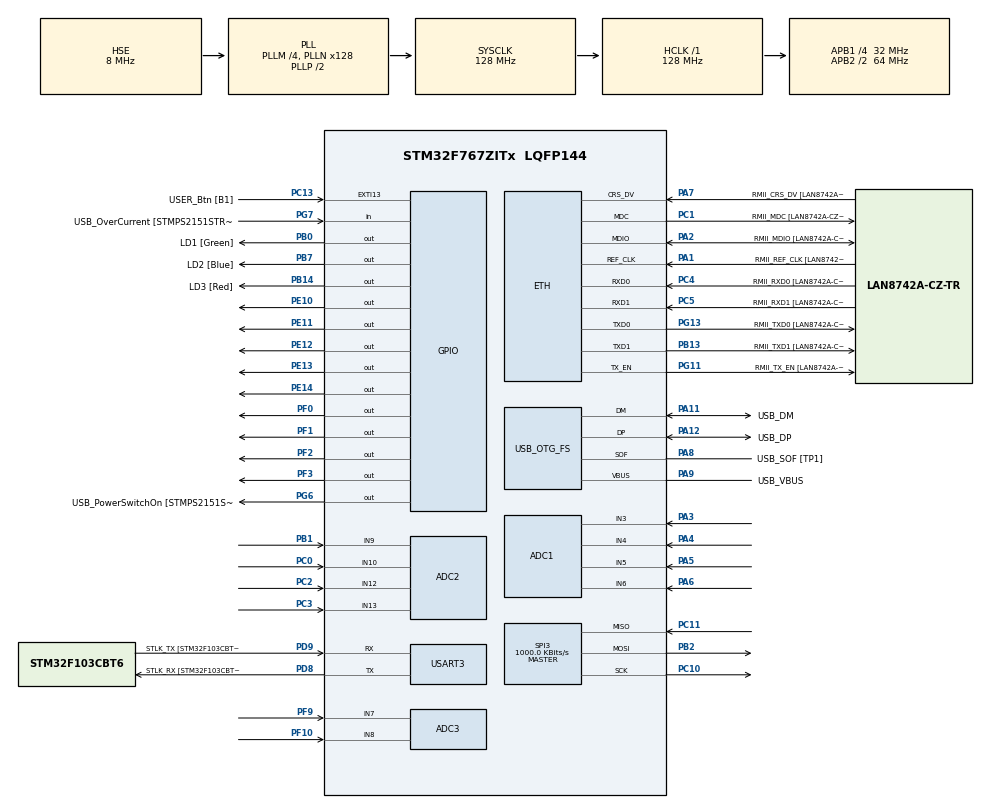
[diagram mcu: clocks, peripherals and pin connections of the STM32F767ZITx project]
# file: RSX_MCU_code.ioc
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ADC1.Channel-4\#ChannelRegularConversion=ADC_CHANNEL_3
ADC1.Channel-5\#ChannelRegularConversion=ADC_CHANNEL_4
ADC1.Channel-6\#ChannelRegularConversion=ADC_CHANNEL_5
ADC1.Channel-7\#ChannelRegularConversion=ADC_CHANNEL_6
ADC1.ClockPrescaler=ADC_CLOCK_SYNC_PCLK_DIV4
ADC1.ContinuousConvMode=ENABLE
ADC1.DMAContinuousRequests=ENABLE
ADC1.NbrOfConversion=4
ADC1.NbrOfConversionFlag=1
ADC1.Rank-4\#ChannelRegularConversion=1
ADC1.Rank-5\#ChannelRegularConversion=2
ADC1.Rank-6\#ChannelRegularConversion=3
ADC1.Rank-7\#ChannelRegularConversion=4
ADC1.SamplingTime-4\#ChannelRegularConversion=ADC_SAMPLETIME_3CYCLES
ADC1.SamplingTime-5\#ChannelRegularConversion=ADC_SAMPLETIME_3CYCLES
ADC1.SamplingTime-6\#ChannelRegularConversion=ADC_SAMPLETIME_3CYCLES
ADC1.SamplingTime-7\#ChannelRegularConversion=ADC_SAMPLETIME_3CYCLES
ADC1.ScanConvMode=ADC_SCAN_ENABLE
ADC1.master=1
ADC2.Channel-1\#ChannelRegularConversion=ADC_CHANNEL_9
ADC2.Channel-2\#ChannelRegularConversion=ADC_CHANNEL_10
ADC2.Channel-3\#ChannelRegularConversion=ADC_CHANNEL_12
ADC2.Channel-4\#ChannelRegularConversion=ADC_CHANNEL_13
ADC2.ClockPrescaler=ADC_CLOCK_SYNC_PCLK_DIV4
ADC2.ContinuousConvMode=ENABLE
ADC2.DMAContinuousRequests=ENABLE
ADC2.NbrOfConversion=4
ADC2.NbrOfConversionFlag=1
ADC2.Rank-1\#ChannelRegularConversion=1
ADC2.Rank-2\#ChannelRegularConversion=2
ADC2.Rank-3\#ChannelRegularConversion=3
ADC2.Rank-4\#ChannelRegularConversion=4
ADC2.SamplingTime-1\#ChannelRegularConversion=ADC_SAMPLETIME_3CYCLES
ADC2.SamplingTime-2\#ChannelRegularConversion=ADC_SAMPLETIME_3CYCLES
ADC2.SamplingTime-3\#ChannelRegularConversion=ADC_SAMPLETIME_3CYCLES
ADC2.SamplingTime-4\#ChannelRegularConversion=ADC_SAMPLETIME_3CYCLES
ADC2.ScanConvMode=ADC_SCAN_ENABLE
ADC3.Channel-0\#ChannelRegularConversion=ADC_CHANNEL_7
ADC3.Channel-1\#ChannelRegularConversion=ADC_CHANNEL_8
ADC3.ClockPrescaler=ADC_CLOCK_SYNC_PCLK_DIV4
ADC3.ContinuousConvMode=ENABLE
ADC3.DMAContinuousRequests=ENABLE
ADC3.NbrOfConversion=2
ADC3.NbrOfConversionFlag=1
ADC3.Rank-0\#ChannelRegularConversion=1
ADC3.Rank-1\#ChannelRegularConversion=2
ADC3.SamplingTime-0\#ChannelRegularConversion=ADC_SAMPLETIME_3CYCLES
ADC3.SamplingTime-1\#ChannelRegularConversion=ADC_SAMPLETIME_3CYCLES
ADC3.ScanConvMode=ADC_SCAN_ENABLE
Dma.ADC1.0.Direction=DMA_PERIPH_TO_MEMORY
Dma.ADC1.0.FIFOMode=DMA_FIFOMODE_DISABLE
Dma.ADC1.0.Instance=DMA2_Stream0
Dma.ADC1.0.MemDataAlignment=DMA_MDATAALIGN_HALFWORD
Dma.ADC1.0.MemInc=DMA_MINC_ENABLE
Dma.ADC1.0.Mode=DMA_NORMAL
Dma.ADC1.0.PeriphDataAlignment=DMA_PDATAALIGN_HALFWORD
Dma.ADC1.0.PeriphInc=DMA_PINC_DISABLE
Dma.ADC1.0.Priority=DMA_PRIORITY_LOW
Dma.ADC2.1.Direction=DMA_PERIPH_TO_MEMORY
Dma.ADC2.1.FIFOMode=DMA_FIFOMODE_DISABLE
Dma.ADC2.1.Instance=DMA2_Stream2
Dma.ADC2.1.MemDataAlignment=DMA_MDATAALIGN_HALFWORD
Dma.ADC2.1.MemInc=DMA_MINC_ENABLE
Dma.ADC2.1.Mode=DMA_NORMAL
Dma.ADC2.1.PeriphDataAlignment=DMA_PDATAALIGN_HALFWORD
Dma.ADC2.1.PeriphInc=DMA_PINC_DISABLE
Dma.ADC2.1.Priority=DMA_PRIORITY_LOW
Dma.ADC3.2.Direction=DMA_PERIPH_TO_MEMORY
Dma.ADC3.2.FIFOMode=DMA_FIFOMODE_DISABLE
Dma.ADC3.2.Instance=DMA2_Stream1
Dma.ADC3.2.MemDataAlignment=DMA_MDATAALIGN_HALFWORD
Dma.ADC3.2.MemInc=DMA_MINC_ENABLE
Dma.ADC3.2.Mode=DMA_NORMAL
Dma.ADC3.2.PeriphDataAlignment=DMA_PDATAALIGN_HALFWORD
Dma.ADC3.2.PeriphInc=DMA_PINC_DISABLE
Dma.ADC3.2.Priority=DMA_PRIORITY_LOW
Dma.Request0=ADC1
Dma.Request1=ADC2
Dma.Request2=ADC3
ETH.MediaInterface=HAL_ETH_RMII_MODE
ETH.PHY_Name=LAN8742A_PHY_ADDRESS
ETH.PHY_Value=0
ETH.PhyAddress=0
Mcu.Family=STM32F7
Mcu.Name=STM32F767ZITx
Mcu.Package=LQFP144
NVIC.DMA2_Stream0_IRQn=true\:0\:0\:false\:false\:true\:false\:true\:true
NVIC.DMA2_Stream1_IRQn=true\:0\:0\:false\:false\:true\:false\:true\:true
NVIC.DMA2_Stream2_IRQn=true\:0\:0\:false\:false\:true\:false\:true\:true
NVIC.PriorityGroup=NVIC_PRIORITYGROUP_4
PA1.GPIO_Label=RMII_REF_CLK [LAN8742A-CZ-TR_REFCLK0]
PA1.Mode=RMII
PA1.Signal=ETH_REF_CLK
PA10.GPIO_Label=USB_ID
PA10.Signal=USB_OTG_FS_ID
PA11.GPIO_Label=USB_DM
PA11.Mode=Device_Only
PA11.Signal=USB_OTG_FS_DM
PA12.GPIO_Label=USB_DP
PA12.Mode=Device_Only
PA12.Signal=USB_OTG_FS_DP
PA13.GPIO_Label=TMS
PA13.Mode=Serial_Wire
PA13.Signal=SYS_JTMS-SWDIO
PA14.GPIO_Label=TCK
PA14.Mode=Serial_Wire
PA14.Signal=SYS_JTCK-SWCLK
PA2.GPIO_Label=RMII_MDIO [LAN8742A-CZ-TR_MDIO]
PA2.Mode=RMII
PA2.Signal=ETH_MDIO
PA3.Signal=ADCx_IN3
PA4.Signal=ADCx_IN4
PA5.Signal=ADCx_IN5
PA6.Signal=ADCx_IN6
PA7.GPIO_Label=RMII_CRS_DV [LAN8742A-CZ-TR_CRS_DV]
PA7.Mode=RMII
PA7.Signal=ETH_CRS_DV
PA8.GPIO_Label=USB_SOF [TP1]
PA8.Mode=Activate_SOF_FS
PA8.Signal=USB_OTG_FS_SOF
PA9.GPIO_Label=USB_VBUS
PA9.Mode=Activate_VBUS
PA9.Signal=USB_OTG_FS_VBUS
PB0.GPIO_Label=LD1 [Green]
PB0.PinState=GPIO_PIN_RESET
PB0.Signal=GPIO_Output
PB1.Signal=ADCx_IN9
PB13.GPIO_Label=RMII_TXD1 [LAN8742A-CZ-TR_TXD1]
PB13.Mode=RMII
PB13.Signal=ETH_TXD1
PB14.GPIO_Label=LD3 [Red]
PB14.Signal=GPIO_Output
PB2.Mode=Full_Duplex_Master
PB2.Signal=SPI3_MOSI
PB3.GPIO_Label=SWO
PB3.Signal=SYS_JTDO-SWO
PB7.GPIO_Label=LD2 [Blue]
PB7.Signal=GPIO_Output
PC0.Signal=ADCx_IN10
PC1.GPIO_Label=RMII_MDC [LAN8742A-CZ-TR_MDC]
PC1.Mode=RMII
PC1.Signal=ETH_MDC
PC10.Mode=Full_Duplex_Master
PC10.Signal=SPI3_SCK
PC11.Mode=Full_Duplex_Master
PC11.Signal=SPI3_MISO
PC13.GPIO_Label=USER_Btn [B1]
PC13.Signal=GPXTI13
PC14/OSC32_IN.Mode=LSE-External-Oscillator
PC14/OSC32_IN.Signal=RCC_OSC32_IN
PC15/OSC32_OUT.Mode=LSE-External-Oscillator
PC15/OSC32_OUT.Signal=RCC_OSC32_OUT
PC2.Signal=ADCx_IN12
PC3.Signal=ADCx_IN13
PC4.GPIO_Label=RMII_RXD0 [LAN8742A-CZ-TR_RXD0]
PC4.Mode=RMII
PC4.Signal=ETH_RXD0
PC5.GPIO_Label=RMII_RXD1 [LAN8742A-CZ-TR_RXD1]
PC5.Mode=RMII
PC5.Signal=ETH_RXD1
PD8.GPIO_Label=STLK_RX [STM32F103CBT6_PA3]
PD8.Mode=Asynchronous
PD8.Signal=USART3_TX
PD9.GPIO_Label=STLK_TX [STM32F103CBT6_PA2]
PD9.Mode=Asynchronous
PD9.Signal=USART3_RX
PE10.Signal=GPIO_Output
PE11.Signal=GPIO_Output
PE12.Signal=GPIO_Output
PE13.Signal=GPIO_Output
PE14.Signal=GPIO_Output
PF0.Signal=GPIO_Output
PF1.Signal=GPIO_Output
PF10.Mode=IN8
PF10.Signal=ADC3_IN8
PF2.Signal=GPIO_Output
PF3.Signal=GPIO_Output
PF9.Mode=IN7
PF9.Signal=ADC3_IN7
PG11.GPIO_Label=RMII_TX_EN [LAN8742A-CZ-TR_TXEN]
PG11.Mode=RMII
PG11.Signal=ETH_TX_EN
PG13.GPIO_Label=RMII_TXD0 [LAN8742A-CZ-TR_TXD0]
PG13.Mode=RMII
PG13.Signal=ETH_TXD0
PG6.GPIO_Label=USB_PowerSwitchOn [STMPS2151STR_EN]
PG6.Signal=GPIO_Output
PG7.GPIO_Label=USB_OverCurrent [STMPS2151STR_FAULT]
PG7.Signal=GPIO_Input
PH0/OSC_IN.GPIO_Label=MCO [STM32F103CBT6_PA8]
PH0/OSC_IN.Mode=HSE-External-Clock-Source
PH0/OSC_IN.Signal=RCC_OSC_IN
PH1/OSC_OUT.Mode=HSE-External-Clock-Source
PH1/OSC_OUT.Signal=RCC_OSC_OUT
ProjectManager.HeapSize=0x200
ProjectManager.StackSize=0x400
ProjectManager.TargetToolchain=STM32CubeIDE
RCC.48MHZClocksFreq_Value=24000000
RCC.AHBFreq_Value=128000000
RCC.APB1CLKDivider=RCC_HCLK_DIV4
RCC.APB1Freq_Value=32000000
RCC.APB1TimFreq_Value=64000000
RCC.APB2CLKDivider=RCC_HCLK_DIV2
RCC.APB2Freq_Value=64000000
RCC.APB2TimFreq_Value=128000000
RCC.CortexFreq_Value=128000000
RCC.HCLKFreq_Value=128000000
RCC.HSE_VALUE=8000000
RCC.HSI_VALUE=16000000
RCC.PLL48CLockSelection=RCC_CLK48SOURCE_PLLSAIP
RCC.PLLM=4
RCC.PLLMUL=RCC_PLL_MUL9
RCC.PLLN=128
RCC.PLLQ=4
RCC.PLLSAIP=RCC_PLLSAIP_DIV8
RCC.PRESCALERUSB=RCC_USBCLKSOURCE_PLL_DIV1_5
RCC.SYSCLKFreq_VALUE=128000000
RCC.SYSCLKSource=RCC_SYSCLKSOURCE_PLLCLK
RCC.SYSCLKSourceVirtual=RCC_SYSCLKSOURCE_PLLCLK
RCC.USBFreq_Value=48000000
RCC.VCOOutputFreq_Value=256000000
SH.ADCx_IN10.0=ADC2_IN10,IN10
SH.ADCx_IN12.0=ADC2_IN12,IN12
SH.ADCx_IN13.0=ADC2_IN13,IN13
SH.ADCx_IN3.0=ADC1_IN3,IN3
SH.ADCx_IN4.0=ADC1_IN4,IN4
SH.ADCx_IN5.0=ADC1_IN5,IN5
SH.ADCx_IN6.0=ADC1_IN6,IN6
SH.ADCx_IN9.0=ADC2_IN9,IN9
SPI3.BaudRatePrescaler=SPI_BAUDRATEPRESCALER_32
SPI3.CalculateBaudRate=1000.0 KBits/s
SPI3.Direction=SPI_DIRECTION_2LINES
SPI3.Mode=SPI_MODE_MASTER
SPI3.VirtualType=VM_MASTER
USART3.VirtualMode-Asynchronous=VM_ASYNC
USB_OTG_FS.VirtualMode=Device_Only
board=NUCLEO-F767ZI

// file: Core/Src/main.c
/* USER CODE BEGIN Header */
/**
  ******************************************************************************
  * @file           : main.c
  * @brief          : Main program body
  ******************************************************************************
  * @attention
  *
  * Copyright (c) 2025 STMicroelectronics.
  * All rights reserved.
  *
  * This software is licensed under terms that can be found in the LICENSE file
  * in the root directory of this software component.
  * If no LICENSE file comes with this software, it is provided AS-IS.
  *
  ******************************************************************************
  */
/* USER CODE END Header */
#include "main.h"
#include "string.h"

/* USER CODE BEGIN Includes */
#include <stdio.h>

/* USER CODE END Includes */

#if defined ( __ICCARM__ ) /*!< IAR Compiler */
#pragma location=0x2007c000
ETH_DMADescTypeDef  DMARxDscrTab[ETH_RX_DESC_CNT]; /* Ethernet Rx DMA Descriptors */
#pragma location=0x2007c0a0
ETH_DMADescTypeDef  DMATxDscrTab[ETH_TX_DESC_CNT]; /* Ethernet Tx DMA Descriptors */

#elif defined ( __CC_ARM )  /* MDK ARM Compiler */

__attribute__((at(0x2007c000))) ETH_DMADescTypeDef  DMARxDscrTab[ETH_RX_DESC_CNT]; /* Ethernet Rx DMA Descriptors */
__attribute__((at(0x2007c0a0))) ETH_DMADescTypeDef  DMATxDscrTab[ETH_TX_DESC_CNT]; /* Ethernet Tx DMA Descriptors */

#elif defined ( __GNUC__ ) /* GNU Compiler */

ETH_DMADescTypeDef DMARxDscrTab[ETH_RX_DESC_CNT] __attribute__((section(".RxDecripSection"))); /* Ethernet Rx DMA Descriptors */
ETH_DMADescTypeDef DMATxDscrTab[ETH_TX_DESC_CNT] __attribute__((section(".TxDecripSection")));   /* Ethernet Tx DMA Descriptors */
#endif

ETH_TxPacketConfig TxConfig;

ADC_HandleTypeDef hadc1;
ADC_HandleTypeDef hadc2;
ADC_HandleTypeDef hadc3;
DMA_HandleTypeDef hdma_adc1;
DMA_HandleTypeDef hdma_adc2;
DMA_HandleTypeDef hdma_adc3;

ETH_HandleTypeDef heth;

SPI_HandleTypeDef hspi3;

UART_HandleTypeDef huart3;

PCD_HandleTypeDef hpcd_USB_OTG_FS;

void SystemClock_Config(void);
static void MX_GPIO_Init(void);
static void MX_DMA_Init(void);
static void MX_ETH_Init(void);
static void MX_USART3_UART_Init(void);
static void MX_USB_OTG_FS_PCD_Init(void);
static void MX_ADC1_Init(void);
static void MX_ADC2_Init(void);
static void MX_ADC3_Init(void);
static void MX_SPI3_Init(void);

int main(void)
{

  /* MCU Configuration--------------------------------------------------------*/

  /* Reset of all peripherals, Initializes the Flash interface and the Systick. */
  HAL_Init();

  /* Configure the system clock */
  SystemClock_Config();

  /* Initialize all configured peripherals */
  MX_GPIO_Init();
  MX_DMA_Init();
  MX_ETH_Init();
  MX_USART3_UART_Init();
  MX_USB_OTG_FS_PCD_Init();
  MX_ADC1_Init();
  MX_ADC2_Init();
  MX_ADC3_Init();
  MX_SPI3_Init();
  /* USER CODE BEGIN 2 */

  HAL_ADC_Start_DMA(&hadc1, adc1_values, 4);
  HAL_ADC_Start_DMA(&hadc2, adc2_values, 4);
  HAL_ADC_Start_DMA(&hadc3, adc3_values, 2);

  /* USER CODE END 2 */

  /* Infinite loop */
  while (1)
  {

    /* USER CODE BEGIN 3 */
	  printf("ADC1: %lu %lu %lu %lu\n", adc1_values[0], adc1_values[1], adc1_values[2], adc1_values[3]);
	  printf("ADC2: %lu %lu %lu %lu\n", adc2_values[0], adc2_values[1], adc2_values[2], adc2_values[3]);
	  printf("ADC3: %lu %lu\n", adc3_values[0], adc3_values[1]);

	  HAL_Delay(500);  // Print every 500ms
  }
  /* USER CODE END 3 */
}

void SystemClock_Config(void)
{
  RCC_OscInitTypeDef RCC_OscInitStruct = {0};
  RCC_ClkInitTypeDef RCC_ClkInitStruct = {0};

  /** Configure LSE Drive Capability
  */
  HAL_PWR_EnableBkUpAccess();

  /** Configure the main internal regulator output voltage
  */
  __HAL_RCC_PWR_CLK_ENABLE();
  __HAL_PWR_VOLTAGESCALING_CONFIG(PWR_REGULATOR_VOLTAGE_SCALE3);

  /** Initializes the RCC Oscillators according to the specified parameters
  * in the RCC_OscInitTypeDef structure.
  */
  RCC_OscInitStruct.OscillatorType = RCC_OSCILLATORTYPE_HSE;
  RCC_OscInitStruct.HSEState = RCC_HSE_BYPASS;
  RCC_OscInitStruct.PLL.PLLState = RCC_PLL_ON;
  RCC_OscInitStruct.PLL.PLLSource = RCC_PLLSOURCE_HSE;
  RCC_OscInitStruct.PLL.PLLM = 4;
  RCC_OscInitStruct.PLL.PLLN = 128;
  RCC_OscInitStruct.PLL.PLLP = RCC_PLLP_DIV2;
  RCC_OscInitStruct.PLL.PLLQ = 4;
  RCC_OscInitStruct.PLL.PLLR = 2;
  if (HAL_RCC_OscConfig(&RCC_OscInitStruct) != HAL_OK)
  {
    Error_Handler();
  }

  /** Initializes the CPU, AHB and APB buses clocks
  */
  RCC_ClkInitStruct.ClockType = RCC_CLOCKTYPE_HCLK|RCC_CLOCKTYPE_SYSCLK
                              |RCC_CLOCKTYPE_PCLK1|RCC_CLOCKTYPE_PCLK2;
  RCC_ClkInitStruct.SYSCLKSource = RCC_SYSCLKSOURCE_PLLCLK;
  RCC_ClkInitStruct.AHBCLKDivider = RCC_SYSCLK_DIV1;
  RCC_ClkInitStruct.APB1CLKDivider = RCC_HCLK_DIV4;
  RCC_ClkInitStruct.APB2CLKDivider = RCC_HCLK_DIV2;

  if (HAL_RCC_ClockConfig(&RCC_ClkInitStruct, FLASH_LATENCY_4) != HAL_OK)
  {
    Error_Handler();
  }
}

static void MX_ADC1_Init(void)
{

  ADC_ChannelConfTypeDef sConfig = {0};

  /** Configure the global features of the ADC (Clock, Resolution, Data Alignment and number of conversion)
  */
  hadc1.Instance = ADC1;
  hadc1.Init.ClockPrescaler = ADC_CLOCK_SYNC_PCLK_DIV4;
  hadc1.Init.Resolution = ADC_RESOLUTION_12B;
  hadc1.Init.ScanConvMode = ADC_SCAN_ENABLE;
  hadc1.Init.ContinuousConvMode = ENABLE;
  hadc1.Init.DiscontinuousConvMode = DISABLE;
  hadc1.Init.ExternalTrigConvEdge = ADC_EXTERNALTRIGCONVEDGE_NONE;
  hadc1.Init.ExternalTrigConv = ADC_SOFTWARE_START;
  hadc1.Init.DataAlign = ADC_DATAALIGN_RIGHT;
  hadc1.Init.NbrOfConversion = 4;
  hadc1.Init.DMAContinuousRequests = ENABLE;
  hadc1.Init.EOCSelection = ADC_EOC_SINGLE_CONV;
  if (HAL_ADC_Init(&hadc1) != HAL_OK)
  {
    Error_Handler();
  }

  /** Configure for the selected ADC regular channel its corresponding rank in the sequencer and its sample time.
  */
  sConfig.Channel = ADC_CHANNEL_3;
  sConfig.Rank = ADC_REGULAR_RANK_1;
  sConfig.SamplingTime = ADC_SAMPLETIME_3CYCLES;
  if (HAL_ADC_ConfigChannel(&hadc1, &sConfig) != HAL_OK)
  {
    Error_Handler();
  }

  /** Configure for the selected ADC regular channel its corresponding rank in the sequencer and its sample time.
  */
  sConfig.Channel = ADC_CHANNEL_4;
  sConfig.Rank = ADC_REGULAR_RANK_2;
  if (HAL_ADC_ConfigChannel(&hadc1, &sConfig) != HAL_OK)
  {
    Error_Handler();
  }

  /** Configure for the selected ADC regular channel its corresponding rank in the sequencer and its sample time.
  */
  sConfig.Channel = ADC_CHANNEL_5;
  sConfig.Rank = ADC_REGULAR_RANK_3;
  if (HAL_ADC_ConfigChannel(&hadc1, &sConfig) != HAL_OK)
  {
    Error_Handler();
  }

  /** Configure for the selected ADC regular channel its corresponding rank in the sequencer and its sample time.
  */
  sConfig.Channel = ADC_CHANNEL_6;
  sConfig.Rank = ADC_REGULAR_RANK_4;
  if (HAL_ADC_ConfigChannel(&hadc1, &sConfig) != HAL_OK)
  {
    Error_Handler();
  }

}

static void MX_ADC2_Init(void)
{

  ADC_ChannelConfTypeDef sConfig = {0};

  /** Configure the global features of the ADC (Clock, Resolution, Data Alignment and number of conversion)
  */
  hadc2.Instance = ADC2;
  hadc2.Init.ClockPrescaler = ADC_CLOCK_SYNC_PCLK_DIV4;
  hadc2.Init.Resolution = ADC_RESOLUTION_12B;
  hadc2.Init.ScanConvMode = ADC_SCAN_ENABLE;
  hadc2.Init.ContinuousConvMode = ENABLE;
  hadc2.Init.DiscontinuousConvMode = DISABLE;
  hadc2.Init.ExternalTrigConvEdge = ADC_EXTERNALTRIGCONVEDGE_NONE;
  hadc2.Init.ExternalTrigConv = ADC_SOFTWARE_START;
  hadc2.Init.DataAlign = ADC_DATAALIGN_RIGHT;
  hadc2.Init.NbrOfConversion = 4;
  hadc2.Init.DMAContinuousRequests = ENABLE;
  hadc2.Init.EOCSelection = ADC_EOC_SINGLE_CONV;
  if (HAL_ADC_Init(&hadc2) != HAL_OK)
  {
    Error_Handler();
  }

  /** Configure for the selected ADC regular channel its corresponding rank in the sequencer and its sample time.
  */
  sConfig.Channel = ADC_CHANNEL_9;
  sConfig.Rank = ADC_REGULAR_RANK_1;
  sConfig.SamplingTime = ADC_SAMPLETIME_3CYCLES;
  if (HAL_ADC_ConfigChannel(&hadc2, &sConfig) != HAL_OK)
  {
    Error_Handler();
  }

  /** Configure for the selected ADC regular channel its corresponding rank in the sequencer and its sample time.
  */
  sConfig.Channel = ADC_CHANNEL_10;
  sConfig.Rank = ADC_REGULAR_RANK_2;
  if (HAL_ADC_ConfigChannel(&hadc2, &sConfig) != HAL_OK)
  {
    Error_Handler();
  }

  /** Configure for the selected ADC regular channel its corresponding rank in the sequencer and its sample time.
  */
  sConfig.Channel = ADC_CHANNEL_12;
  sConfig.Rank = ADC_REGULAR_RANK_3;
  if (HAL_ADC_ConfigChannel(&hadc2, &sConfig) != HAL_OK)
  {
    Error_Handler();
  }

  /** Configure for the selected ADC regular channel its corresponding rank in the sequencer and its sample time.
  */
  sConfig.Channel = ADC_CHANNEL_13;
  sConfig.Rank = ADC_REGULAR_RANK_4;
  if (HAL_ADC_ConfigChannel(&hadc2, &sConfig) != HAL_OK)
  {
    Error_Handler();
  }

}

static void MX_ADC3_Init(void)
{

  ADC_ChannelConfTypeDef sConfig = {0};

  /** Configure the global features of the ADC (Clock, Resolution, Data Alignment and number of conversion)
  */
  hadc3.Instance = ADC3;
  hadc3.Init.ClockPrescaler = ADC_CLOCK_SYNC_PCLK_DIV4;
  hadc3.Init.Resolution = ADC_RESOLUTION_12B;
  hadc3.Init.ScanConvMode = ADC_SCAN_ENABLE;
  hadc3.Init.ContinuousConvMode = ENABLE;
  hadc3.Init.DiscontinuousConvMode = DISABLE;
  hadc3.Init.ExternalTrigConvEdge = ADC_EXTERNALTRIGCONVEDGE_NONE;
  hadc3.Init.ExternalTrigConv = ADC_SOFTWARE_START;
  hadc3.Init.DataAlign = ADC_DATAALIGN_RIGHT;
  hadc3.Init.NbrOfConversion = 2;
  hadc3.Init.DMAContinuousRequests = ENABLE;
  hadc3.Init.EOCSelection = ADC_EOC_SINGLE_CONV;
  if (HAL_ADC_Init(&hadc3) != HAL_OK)
  {
    Error_Handler();
  }

  /** Configure for the selected ADC regular channel its corresponding rank in the sequencer and its sample time.
  */
  sConfig.Channel = ADC_CHANNEL_7;
  sConfig.Rank = ADC_REGULAR_RANK_1;
  sConfig.SamplingTime = ADC_SAMPLETIME_3CYCLES;
  if (HAL_ADC_ConfigChannel(&hadc3, &sConfig) != HAL_OK)
  {
    Error_Handler();
  }

  /** Configure for the selected ADC regular channel its corresponding rank in the sequencer and its sample time.
  */
  sConfig.Channel = ADC_CHANNEL_8;
  sConfig.Rank = ADC_REGULAR_RANK_2;
  if (HAL_ADC_ConfigChannel(&hadc3, &sConfig) != HAL_OK)
  {
    Error_Handler();
  }

}

static void MX_ETH_Init(void)
{

   static uint8_t MACAddr[6];

  heth.Instance = ETH;
  MACAddr[0] = 0x00;
  MACAddr[1] = 0x80;
  MACAddr[2] = 0xE1;
  MACAddr[3] = 0x00;
  MACAddr[4] = 0x00;
  MACAddr[5] = 0x00;
  heth.Init.MACAddr = &MACAddr[0];
  heth.Init.MediaInterface = HAL_ETH_RMII_MODE;
  heth.Init.TxDesc = DMATxDscrTab;
  heth.Init.RxDesc = DMARxDscrTab;
  heth.Init.RxBuffLen = 1524;

  if (HAL_ETH_Init(&heth) != HAL_OK)
  {
    Error_Handler();
  }

  memset(&TxConfig, 0 , sizeof(ETH_TxPacketConfig));
  TxConfig.Attributes = ETH_TX_PACKETS_FEATURES_CSUM | ETH_TX_PACKETS_FEATURES_CRCPAD;
  TxConfig.ChecksumCtrl = ETH_CHECKSUM_IPHDR_PAYLOAD_INSERT_PHDR_CALC;
  TxConfig.CRCPadCtrl = ETH_CRC_PAD_INSERT;

}

static void MX_SPI3_Init(void)
{

  /* SPI3 parameter configuration*/
  hspi3.Instance = SPI3;
  hspi3.Init.Mode = SPI_MODE_MASTER;
  hspi3.Init.Direction = SPI_DIRECTION_2LINES;
  hspi3.Init.DataSize = SPI_DATASIZE_4BIT;
  hspi3.Init.CLKPolarity = SPI_POLARITY_LOW;
  hspi3.Init.CLKPhase = SPI_PHASE_1EDGE;
  hspi3.Init.NSS = SPI_NSS_SOFT;
  hspi3.Init.BaudRatePrescaler = SPI_BAUDRATEPRESCALER_32;
  hspi3.Init.FirstBit = SPI_FIRSTBIT_MSB;
  hspi3.Init.TIMode = SPI_TIMODE_DISABLE;
  hspi3.Init.CRCCalculation = SPI_CRCCALCULATION_DISABLE;
  hspi3.Init.CRCPolynomial = 7;
  hspi3.Init.CRCLength = SPI_CRC_LENGTH_DATASIZE;
  hspi3.Init.NSSPMode = SPI_NSS_PULSE_ENABLE;
  if (HAL_SPI_Init(&hspi3) != HAL_OK)
  {
    Error_Handler();
  }

}

static void MX_USART3_UART_Init(void)
{

  huart3.Instance = USART3;
  huart3.Init.BaudRate = 115200;
  huart3.Init.WordLength = UART_WORDLENGTH_8B;
  huart3.Init.StopBits = UART_STOPBITS_1;
  huart3.Init.Parity = UART_PARITY_NONE;
  huart3.Init.Mode = UART_MODE_TX_RX;
  huart3.Init.HwFlowCtl = UART_HWCONTROL_NONE;
  huart3.Init.OverSampling = UART_OVERSAMPLING_16;
  huart3.Init.OneBitSampling = UART_ONE_BIT_SAMPLE_DISABLE;
  huart3.AdvancedInit.AdvFeatureInit = UART_ADVFEATURE_NO_INIT;
  if (HAL_UART_Init(&huart3) != HAL_OK)
  {
    Error_Handler();
  }

}

static void MX_USB_OTG_FS_PCD_Init(void)
{

  hpcd_USB_OTG_FS.Instance = USB_OTG_FS;
  hpcd_USB_OTG_FS.Init.dev_endpoints = 6;
  hpcd_USB_OTG_FS.Init.speed = PCD_SPEED_FULL;
  hpcd_USB_OTG_FS.Init.dma_enable = DISABLE;
  hpcd_USB_OTG_FS.Init.phy_itface = PCD_PHY_EMBEDDED;
  hpcd_USB_OTG_FS.Init.Sof_enable = ENABLE;
  hpcd_USB_OTG_FS.Init.low_power_enable = DISABLE;
  hpcd_USB_OTG_FS.Init.lpm_enable = DISABLE;
  hpcd_USB_OTG_FS.Init.vbus_sensing_enable = ENABLE;
  hpcd_USB_OTG_FS.Init.use_dedicated_ep1 = DISABLE;
  if (HAL_PCD_Init(&hpcd_USB_OTG_FS) != HAL_OK)
  {
    Error_Handler();
  }

}

static void MX_DMA_Init(void)
{

  /* DMA controller clock enable */
  __HAL_RCC_DMA2_CLK_ENABLE();

  /* DMA interrupt init */
  /* DMA2_Stream0_IRQn interrupt configuration */
  HAL_NVIC_SetPriority(DMA2_Stream0_IRQn, 0, 0);
  HAL_NVIC_EnableIRQ(DMA2_Stream0_IRQn);
  /* DMA2_Stream1_IRQn interrupt configuration */
  HAL_NVIC_SetPriority(DMA2_Stream1_IRQn, 0, 0);
  HAL_NVIC_EnableIRQ(DMA2_Stream1_IRQn);
  /* DMA2_Stream2_IRQn interrupt configuration */
  HAL_NVIC_SetPriority(DMA2_Stream2_IRQn, 0, 0);
  HAL_NVIC_EnableIRQ(DMA2_Stream2_IRQn);

}

static void MX_GPIO_Init(void)
{
  GPIO_InitTypeDef GPIO_InitStruct = {0};

  /* GPIO Ports Clock Enable */
  __HAL_RCC_GPIOC_CLK_ENABLE();
  __HAL_RCC_GPIOF_CLK_ENABLE();
  __HAL_RCC_GPIOH_CLK_ENABLE();
  __HAL_RCC_GPIOA_CLK_ENABLE();
  __HAL_RCC_GPIOB_CLK_ENABLE();
  __HAL_RCC_GPIOE_CLK_ENABLE();
  __HAL_RCC_GPIOD_CLK_ENABLE();
  __HAL_RCC_GPIOG_CLK_ENABLE();

  /*Configure GPIO pin Output Level */
  HAL_GPIO_WritePin(GPIOF, GPIO_PIN_0|GPIO_PIN_1|GPIO_PIN_2|GPIO_PIN_3, GPIO_PIN_RESET);

  /*Configure GPIO pin Output Level */
  HAL_GPIO_WritePin(GPIOB, LD1_Pin|LD3_Pin|LD2_Pin, GPIO_PIN_RESET);

  /*Configure GPIO pin Output Level */
  HAL_GPIO_WritePin(GPIOE, GPIO_PIN_10|GPIO_PIN_11|GPIO_PIN_12|GPIO_PIN_13
                          |GPIO_PIN_14, GPIO_PIN_RESET);

  /*Configure GPIO pin Output Level */
  HAL_GPIO_WritePin(USB_PowerSwitchOn_GPIO_Port, USB_PowerSwitchOn_Pin, GPIO_PIN_RESET);

  /*Configure GPIO pin : USER_Btn_Pin */
  GPIO_InitStruct.Pin = USER_Btn_Pin;
  GPIO_InitStruct.Mode = GPIO_MODE_IT_RISING;
  GPIO_InitStruct.Pull = GPIO_NOPULL;
  HAL_GPIO_Init(USER_Btn_GPIO_Port, &GPIO_InitStruct);

  /*Configure GPIO pins : PF0 PF1 PF2 PF3 */
  GPIO_InitStruct.Pin = GPIO_PIN_0|GPIO_PIN_1|GPIO_PIN_2|GPIO_PIN_3;
  GPIO_InitStruct.Mode = GPIO_MODE_OUTPUT_PP;
  GPIO_InitStruct.Pull = GPIO_NOPULL;
  GPIO_InitStruct.Speed = GPIO_SPEED_FREQ_LOW;
  HAL_GPIO_Init(GPIOF, &GPIO_InitStruct);

  /*Configure GPIO pins : LD1_Pin LD3_Pin LD2_Pin */
  GPIO_InitStruct.Pin = LD1_Pin|LD3_Pin|LD2_Pin;
  GPIO_InitStruct.Mode = GPIO_MODE_OUTPUT_PP;
  GPIO_InitStruct.Pull = GPIO_NOPULL;
  GPIO_InitStruct.Speed = GPIO_SPEED_FREQ_LOW;
  HAL_GPIO_Init(GPIOB, &GPIO_InitStruct);

  /*Configure GPIO pins : PE10 PE11 PE12 PE13
                           PE14 */
  GPIO_InitStruct.Pin = GPIO_PIN_10|GPIO_PIN_11|GPIO_PIN_12|GPIO_PIN_13
                          |GPIO_PIN_14;
  GPIO_InitStruct.Mode = GPIO_MODE_OUTPUT_PP;
  GPIO_InitStruct.Pull = GPIO_NOPULL;
  GPIO_InitStruct.Speed = GPIO_SPEED_FREQ_LOW;
  HAL_GPIO_Init(GPIOE, &GPIO_InitStruct);

  /*Configure GPIO pin : USB_PowerSwitchOn_Pin */
  GPIO_InitStruct.Pin = USB_PowerSwitchOn_Pin;
  GPIO_InitStruct.Mode = GPIO_MODE_OUTPUT_PP;
  GPIO_InitStruct.Pull = GPIO_NOPULL;
  GPIO_InitStruct.Speed = GPIO_SPEED_FREQ_LOW;
  HAL_GPIO_Init(USB_PowerSwitchOn_GPIO_Port, &GPIO_InitStruct);

  /*Configure GPIO pin : USB_OverCurrent_Pin */
  GPIO_InitStruct.Pin = USB_OverCurrent_Pin;
  GPIO_InitStruct.Mode = GPIO_MODE_INPUT;
  GPIO_InitStruct.Pull = GPIO_NOPULL;
  HAL_GPIO_Init(USB_OverCurrent_GPIO_Port, &GPIO_InitStruct);

}

void Error_Handler(void)
{
  __disable_irq();
  while (1)
  {
  }
}
